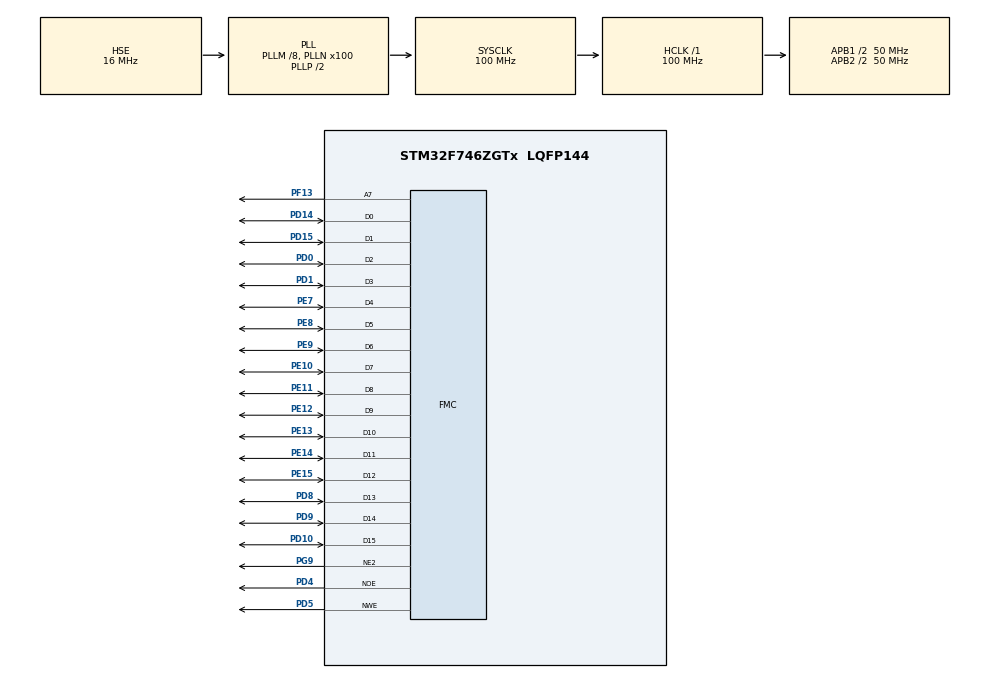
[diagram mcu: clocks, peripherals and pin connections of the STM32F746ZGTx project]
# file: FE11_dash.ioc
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Mcu.Family=STM32F7
Mcu.Name=STM32F746ZGTx
Mcu.Package=LQFP144
NVIC.PriorityGroup=NVIC_PRIORITYGROUP_4
PA13.Mode=Serial_Wire
PA13.Signal=SYS_JTMS-SWDIO
PA14.Mode=Serial_Wire
PA14.Signal=SYS_JTCK-SWCLK
PD0.Signal=FMC_D2_DA2
PD1.Signal=FMC_D3_DA3
PD10.Signal=FMC_D15_DA15
PD14.Signal=FMC_D0_DA0
PD15.Signal=FMC_D1_DA1
PD4.Signal=FMC_NOE
PD5.Signal=FMC_NWE
PD7.Signal=FMC_NE1
PD8.Signal=FMC_D13_DA13
PD9.Signal=FMC_D14_DA14
PE10.Signal=FMC_D7_DA7
PE11.Signal=FMC_D8_DA8
PE12.Signal=FMC_D9_DA9
PE13.Signal=FMC_D10_DA10
PE14.Signal=FMC_D11_DA11
PE15.Signal=FMC_D12_DA12
PE7.Signal=FMC_D4_DA4
PE8.Signal=FMC_D5_DA5
PE9.Signal=FMC_D6_DA6
PF13.Signal=FMC_A7
PG9.Mode=NorPsramChipSelect2_1
PG9.Signal=FMC_NE2
PH0/OSC_IN.Mode=HSE-External-Oscillator
PH0/OSC_IN.Signal=RCC_OSC_IN
PH1/OSC_OUT.Mode=HSE-External-Oscillator
PH1/OSC_OUT.Signal=RCC_OSC_OUT
ProjectManager.HeapSize=0x200
ProjectManager.StackSize=0x400
ProjectManager.TargetToolchain=STM32CubeIDE
RCC.AHBFreq_Value=100000000
RCC.APB1CLKDivider=RCC_HCLK_DIV2
RCC.APB1Freq_Value=50000000
RCC.APB1TimFreq_Value=100000000
RCC.APB2CLKDivider=RCC_HCLK_DIV2
RCC.APB2Freq_Value=50000000
RCC.APB2TimFreq_Value=100000000
RCC.CortexFreq_Value=100000000
RCC.HCLKFreq_Value=100000000
RCC.HSE_VALUE=16000000
RCC.HSI_VALUE=16000000
RCC.LSE_VALUE=32768
RCC.PLLM=8
RCC.PLLN=100
RCC.PLLSourceVirtual=RCC_PLLSOURCE_HSE
RCC.SYSCLKFreq_VALUE=100000000
RCC.SYSCLKSource=RCC_SYSCLKSOURCE_PLLCLK
RCC.USBFreq_Value=100000000
RCC.VCOOutputFreq_Value=200000000
SH.FMC_A7.0=FMC_A7,A7_1
SH.FMC_D0_DA0.0=FMC_D0,16b-d1
SH.FMC_D10_DA10.0=FMC_D10,16b-d1
SH.FMC_D11_DA11.0=FMC_D11,16b-d1
SH.FMC_D12_DA12.0=FMC_D12,16b-d1
SH.FMC_D13_DA13.0=FMC_D13,16b-d1
SH.FMC_D14_DA14.0=FMC_D14,16b-d1
SH.FMC_D15_DA15.0=FMC_D15,16b-d1
SH.FMC_D1_DA1.0=FMC_D1,16b-d1
SH.FMC_D2_DA2.0=FMC_D2,16b-d1
SH.FMC_D3_DA3.0=FMC_D3,16b-d1
SH.FMC_D4_DA4.0=FMC_D4,16b-d1
SH.FMC_D5_DA5.0=FMC_D5,16b-d1
SH.FMC_D6_DA6.0=FMC_D6,16b-d1
SH.FMC_D7_DA7.0=FMC_D7,16b-d1
SH.FMC_D8_DA8.0=FMC_D8,16b-d1
SH.FMC_D9_DA9.0=FMC_D9,16b-d1
SH.FMC_NOE.0=FMC_NOE,Lcd1
SH.FMC_NWE.0=FMC_NWE,Lcd1
board=custom

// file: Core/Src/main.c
/* USER CODE BEGIN Header */
/**
  ******************************************************************************
  * @file           : main.c
  * @brief          : Main program body
  ******************************************************************************
  * @attention
  *
  * Copyright (c) 2024 STMicroelectronics.
  * All rights reserved.
  *
  * This software is licensed under terms that can be found in the LICENSE file
  * in the root directory of this software component.
  * If no LICENSE file comes with this software, it is provided AS-IS.
  *
  ******************************************************************************
  */
/* USER CODE END Header */
#include "main.h"

/* USER CODE BEGIN Includes */

#include "frucd_display.h"

/* USER CODE END Includes */

SRAM_HandleTypeDef hsram1;

void SystemClock_Config(void);
static void MX_GPIO_Init(void);
static void MX_FMC_Init(void);

int main(void)
{

  /* MCU Configuration--------------------------------------------------------*/

  /* Reset of all peripherals, Initializes the Flash interface and the Systick. */
  HAL_Init();

  /* Configure the system clock */
  SystemClock_Config();

  /* Initialize all configured peripherals */
  MX_GPIO_Init();
  MX_FMC_Init();
  /* USER CODE BEGIN 2 */

  Display_Init();

    UG_FontSelect(&FONT_32X53);
    UG_SetBackcolor(C_BLACK);
    UG_SetForecolor(C_WHITE);

    Display_CalibrateScreen();
    HAL_Delay(5000);

    //Display_DriveTemplate();

  /* USER CODE END 2 */

  /* Infinite loop */
  /* USER CODE BEGIN WHILE */
  while (1)
  {
//	  UG_FillScreen(C_BLUE);
//	  HAL_Delay(100);
//	  UG_FillScreen(C_GREEN);
//	  HAL_Delay(100);
//	  UG_FillScreen(C_RED);
//	  HAL_Delay(100);
	  UG_PutString(0, 0, "Hello");
	  UG_PutColorString(50, 50, "It's working", C_RED, C_WHITE);
	  UG_PutColorString(0, 110, "still working", C_BLACK, C_WHITE);
	  HAL_Delay(1000);

    /* USER CODE END WHILE */

  }
}

void SystemClock_Config(void)
{
  RCC_OscInitTypeDef RCC_OscInitStruct = {0};
  RCC_ClkInitTypeDef RCC_ClkInitStruct = {0};

  /** Configure the main internal regulator output voltage
  */
  __HAL_RCC_PWR_CLK_ENABLE();
  __HAL_PWR_VOLTAGESCALING_CONFIG(PWR_REGULATOR_VOLTAGE_SCALE3);

  /** Initializes the RCC Oscillators according to the specified parameters
  * in the RCC_OscInitTypeDef structure.
  */
  RCC_OscInitStruct.OscillatorType = RCC_OSCILLATORTYPE_HSE;
  RCC_OscInitStruct.HSEState = RCC_HSE_ON;
  RCC_OscInitStruct.PLL.PLLState = RCC_PLL_ON;
  RCC_OscInitStruct.PLL.PLLSource = RCC_PLLSOURCE_HSE;
  RCC_OscInitStruct.PLL.PLLM = 8;
  RCC_OscInitStruct.PLL.PLLN = 100;
  RCC_OscInitStruct.PLL.PLLP = RCC_PLLP_DIV2;
  RCC_OscInitStruct.PLL.PLLQ = 2;
  if (HAL_RCC_OscConfig(&RCC_OscInitStruct) != HAL_OK)
  {
    Error_Handler();
  }

  /** Activate the Over-Drive mode
  */
  if (HAL_PWREx_EnableOverDrive() != HAL_OK)
  {
    Error_Handler();
  }

  /** Initializes the CPU, AHB and APB buses clocks
  */
  RCC_ClkInitStruct.ClockType = RCC_CLOCKTYPE_HCLK|RCC_CLOCKTYPE_SYSCLK
                              |RCC_CLOCKTYPE_PCLK1|RCC_CLOCKTYPE_PCLK2;
  RCC_ClkInitStruct.SYSCLKSource = RCC_SYSCLKSOURCE_PLLCLK;
  RCC_ClkInitStruct.AHBCLKDivider = RCC_SYSCLK_DIV1;
  RCC_ClkInitStruct.APB1CLKDivider = RCC_HCLK_DIV2;
  RCC_ClkInitStruct.APB2CLKDivider = RCC_HCLK_DIV2;

  if (HAL_RCC_ClockConfig(&RCC_ClkInitStruct, FLASH_LATENCY_3) != HAL_OK)
  {
    Error_Handler();
  }
}

/* FMC initialization function */
static void MX_FMC_Init(void)
{

  FMC_NORSRAM_TimingTypeDef Timing = {0};

  /** Perform the SRAM1 memory initialization sequence
  */
  hsram1.Instance = FMC_NORSRAM_DEVICE;
  hsram1.Extended = FMC_NORSRAM_EXTENDED_DEVICE;
  /* hsram1.Init */
  hsram1.Init.NSBank = FMC_NORSRAM_BANK2;
  hsram1.Init.DataAddressMux = FMC_DATA_ADDRESS_MUX_DISABLE;
  hsram1.Init.MemoryType = FMC_MEMORY_TYPE_SRAM;
  hsram1.Init.MemoryDataWidth = FMC_NORSRAM_MEM_BUS_WIDTH_16;
  hsram1.Init.BurstAccessMode = FMC_BURST_ACCESS_MODE_DISABLE;
  hsram1.Init.WaitSignalPolarity = FMC_WAIT_SIGNAL_POLARITY_LOW;
  hsram1.Init.WaitSignalActive = FMC_WAIT_TIMING_BEFORE_WS;
  hsram1.Init.WriteOperation = FMC_WRITE_OPERATION_ENABLE;
  hsram1.Init.WaitSignal = FMC_WAIT_SIGNAL_DISABLE;
  hsram1.Init.ExtendedMode = FMC_EXTENDED_MODE_DISABLE;
  hsram1.Init.AsynchronousWait = FMC_ASYNCHRONOUS_WAIT_DISABLE;
  hsram1.Init.WriteBurst = FMC_WRITE_BURST_DISABLE;
  hsram1.Init.ContinuousClock = FMC_CONTINUOUS_CLOCK_SYNC_ONLY;
  hsram1.Init.WriteFifo = FMC_WRITE_FIFO_ENABLE;
  hsram1.Init.PageSize = FMC_PAGE_SIZE_NONE;
  /* Timing */
  Timing.AddressSetupTime = 15;
  Timing.AddressHoldTime = 15;
  Timing.DataSetupTime = 255;
  Timing.BusTurnAroundDuration = 15;
  Timing.CLKDivision = 16;
  Timing.DataLatency = 17;
  Timing.AccessMode = FMC_ACCESS_MODE_A;
  /* ExtTiming */

  if (HAL_SRAM_Init(&hsram1, &Timing, NULL) != HAL_OK)
  {
    Error_Handler( );
  }

}

static void MX_GPIO_Init(void)
{

  /* GPIO Ports Clock Enable */
  __HAL_RCC_GPIOH_CLK_ENABLE();
  __HAL_RCC_GPIOF_CLK_ENABLE();
  __HAL_RCC_GPIOE_CLK_ENABLE();
  __HAL_RCC_GPIOD_CLK_ENABLE();
  __HAL_RCC_GPIOA_CLK_ENABLE();
  __HAL_RCC_GPIOG_CLK_ENABLE();

}

void Error_Handler(void)
{
  __disable_irq();
  while (1)
  {
  }
}
